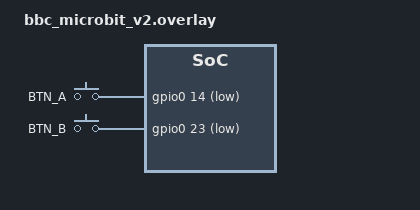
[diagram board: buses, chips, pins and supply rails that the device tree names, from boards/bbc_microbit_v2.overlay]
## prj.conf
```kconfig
#
# Copyright (c) 2018 Nordic Semiconductor
#
# SPDX-License-Identifier: LicenseRef-Nordic-5-Clause
#
CONFIG_NCS_SAMPLES_DEFAULTS=y

CONFIG_BT=y
CONFIG_BT_PERIPHERAL=y
CONFIG_BT_DEVICE_NAME="Nordic_LBS"

# Enable the LBS service
CONFIG_BT_LBS=y
CONFIG_BT_LBS_POLL_BUTTON=y
CONFIG_DK_LIBRARY=y

CONFIG_SYSTEM_WORKQUEUE_STACK_SIZE=2048

CONFIG_DISPLAY=y
CONFIG_MICROBIT_DISPLAY=y
CONFIG_BT_CTLR_TX_PWR_PLUS_8=y
```

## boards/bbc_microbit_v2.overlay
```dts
/*
 * Copyright (c) 2021 Nordic Semiconductor ASA
 *
 * SPDX-License-Identifier: LicenseRef-Nordic-5-Clause
 */

/ {
	buttons {
		compatible = "gpio-keys";
		button0: button_0 {
			label = "BTN_A";
			gpios = <&gpio0 14 GPIO_ACTIVE_LOW>;
			zephyr,code = <INPUT_KEY_A>;
		};

		button1: button_1 {
			label = "BTN_B";
			gpios = <&gpio0 23 GPIO_ACTIVE_LOW>;
			zephyr,code = <INPUT_KEY_B>;
		};
	};
};
```

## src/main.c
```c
/*
 * Copyright (c) 2018 Nordic Semiconductor ASA
 *
 * SPDX-License-Identifier: LicenseRef-Nordic-5-Clause
 */

#include <zephyr/types.h>
#include <stddef.h>
#include <string.h>
#include <errno.h>
#include <zephyr/sys/printk.h>
#include <zephyr/sys/byteorder.h>
#include <zephyr/kernel.h>
#include <zephyr/drivers/gpio.h>
#include <soc.h>

#include <zephyr/bluetooth/bluetooth.h>
#include <zephyr/bluetooth/hci.h>
#include <zephyr/bluetooth/conn.h>
#include <zephyr/bluetooth/uuid.h>
#include <zephyr/bluetooth/gatt.h>

#include <bluetooth/services/lbs.h>

#include <zephyr/settings/settings.h>

#include <dk_buttons_and_leds.h>

#include <zephyr/display/mb_display.h>

#define DEVICE_NAME             CONFIG_BT_DEVICE_NAME
#define DEVICE_NAME_LEN         (sizeof(DEVICE_NAME) - 1)


#define RUN_STATUS_LED          DK_LED1
#define CON_STATUS_LED          DK_LED2
#define RUN_LED_BLINK_INTERVAL  1000

#define USER_LED                DK_LED3

#define USER_BUTTON             DK_BTN1_MSK

static struct mb_image light_on = MB_IMAGE(
					 { 0, 1, 1, 1, 0 },
					 { 1, 0, 0, 0, 1 },
					 { 1, 0, 0, 0, 1 },
					 { 0, 1, 1, 1, 0 },
					 { 0, 1, 1, 1, 0 });

static struct mb_image light_off = MB_IMAGE(
					 { 0, 0, 0, 0, 0 },
					 { 0, 0, 0, 0, 0 },
					 { 0, 0, 0, 0, 0 },
					 { 0, 1, 1, 1, 0 },
					 { 0, 1, 1, 1, 0 });

static struct mb_image ble_disconnected = MB_IMAGE(
					 { 1, 0, 0, 0, 0 },
					 { 0, 0, 0, 0, 0 },
					 { 0, 0, 0, 0, 0 },
					 { 0, 0, 0, 0, 0 },
					 { 0, 0, 0, 0, 0 });

static struct mb_image blank = MB_IMAGE(
					 { 0, 0, 0, 0, 0 },
					 { 0, 0, 0, 0, 0 },
					 { 0, 0, 0, 0, 0 },
					 { 0, 0, 0, 0, 0 },
					 { 0, 0, 0, 0, 0 });

static bool app_button_state;
static bool app_led_state;
static bool ble_conn_state;
static struct mb_display *disp;

static const struct bt_data ad[] = {
	BT_DATA_BYTES(BT_DATA_FLAGS, (BT_LE_AD_GENERAL | BT_LE_AD_NO_BREDR)),
	BT_DATA(BT_DATA_NAME_COMPLETE, DEVICE_NAME, DEVICE_NAME_LEN),
};

static const struct bt_data sd[] = {
	BT_DATA_BYTES(BT_DATA_UUID128_ALL, BT_UUID_LBS_VAL),
};

static void connected(struct bt_conn *conn, uint8_t err)
{
	if (err) {
		printk("Connection failed (err %u)\n", err);
		return;
	}

	printk("Connected\n");

	if (app_led_state) {
		mb_display_image(disp, MB_DISPLAY_FLAG_LOOP, 5 * MSEC_PER_SEC,
				&light_on, 1);
	} else {
		mb_display_image(disp, MB_DISPLAY_FLAG_LOOP, 5 * MSEC_PER_SEC,
				&light_off, 1);
	}
	ble_conn_state = true;
}

static void disconnected(struct bt_conn *conn, uint8_t reason)
{
	printk("Disconnected (reason %u)\n", reason);

	//dk_set_led_off(CON_STATUS_LED);
	ble_conn_state = false;
}

#ifdef CONFIG_BT_LBS_SECURITY_ENABLED
static void security_changed(struct bt_conn *conn, bt_security_t level,
			     enum bt_security_err err)
{
	char addr[BT_ADDR_LE_STR_LEN];

	bt_addr_le_to_str(bt_conn_get_dst(conn), addr, sizeof(addr));

	if (!err) {
		printk("Security changed: %s level %u\n", addr, level);
	} else {
		printk("Security failed: %s level %u err %d\n", addr, level,
			err);
	}
}
#endif

BT_CONN_CB_DEFINE(conn_callbacks) = {
	.connected        = connected,
	.disconnected     = disconnected,
#ifdef CONFIG_BT_LBS_SECURITY_ENABLED
	.security_changed = security_changed,
#endif
};

#if defined(CONFIG_BT_LBS_SECURITY_ENABLED)
static void auth_passkey_display(struct bt_conn *conn, unsigned int passkey)
{
	char addr[BT_ADDR_LE_STR_LEN];

	bt_addr_le_to_str(bt_conn_get_dst(conn), addr, sizeof(addr));

	printk("Passkey for %s: %06u\n", addr, passkey);
}

static void auth_cancel(struct bt_conn *conn)
{
	char addr[BT_ADDR_LE_STR_LEN];

	bt_addr_le_to_str(bt_conn_get_dst(conn), addr, sizeof(addr));

	printk("Pairing cancelled: %s\n", addr);
}

static void pairing_complete(struct bt_conn *conn, bool bonded)
{
	char addr[BT_ADDR_LE_STR_LEN];

	bt_addr_le_to_str(bt_conn_get_dst(conn), addr, sizeof(addr));

	printk("Pairing completed: %s, bonded: %d\n", addr, bonded);
}

static void pairing_failed(struct bt_conn *conn, enum bt_security_err reason)
{
	char addr[BT_ADDR_LE_STR_LEN];

	bt_addr_le_to_str(bt_conn_get_dst(conn), addr, sizeof(addr));

	printk("Pairing failed conn: %s, reason %d\n", addr, reason);
}

static struct bt_conn_auth_cb conn_auth_callbacks = {
	.passkey_display = auth_passkey_display,
	.cancel = auth_cancel,
};

static struct bt_conn_auth_info_cb conn_auth_info_callbacks = {
	.pairing_complete = pairing_complete,
	.pairing_failed = pairing_failed
};
#else
static struct bt_conn_auth_cb conn_auth_callbacks;
static struct bt_conn_auth_info_cb conn_auth_info_callbacks;
#endif

static void app_led_cb(bool led_state)
{
	printk("led state: %d\n", led_state);
	app_led_state = led_state;
	if (app_led_state) {
		mb_display_image(disp, MB_DISPLAY_FLAG_LOOP, 5 * MSEC_PER_SEC,
				&light_on, 1);
	} else {
		mb_display_image(disp, MB_DISPLAY_FLAG_LOOP, 5 * MSEC_PER_SEC,
				&light_off, 1);
	}
}

static bool app_button_cb(void)
{
	return app_button_state;
}

static struct bt_lbs_cb lbs_callbacs = {
	.led_cb    = app_led_cb,
	.button_cb = app_button_cb,
};

static void button_changed(uint32_t button_state, uint32_t has_changed)
{
	if (has_changed & USER_BUTTON) {
		uint32_t user_button_state = button_state & USER_BUTTON;

		bt_lbs_send_button_state(user_button_state);
		app_button_state = user_button_state ? true : false;
		printk("app_button_state: %d\n", app_button_state);
	}
}

static int init_button(void)
{
	int err;

	err = dk_buttons_init(button_changed);
	if (err) {
		printk("Cannot init buttons (err: %d)\n", err);
	}

	return err;
}

int main(void)
{
	int blink_status = 0;
	int err;

	printk("Starting Bluetooth Peripheral LBS example\n");

	disp = mb_display_get();

	err = init_button();
	if (err) {
		printk("Button init failed (err %d)\n", err);
		return 0;
	}

	if (IS_ENABLED(CONFIG_BT_LBS_SECURITY_ENABLED)) {
		err = bt_conn_auth_cb_register(&conn_auth_callbacks);
		if (err) {
			printk("Failed to register authorization callbacks.\n");
			return 0;
		}

		err = bt_conn_auth_info_cb_register(&conn_auth_info_callbacks);
		if (err) {
			printk("Failed to register authorization info callbacks.\n");
			return 0;
		}
	}

	err = bt_enable(NULL);
	if (err) {
		printk("Bluetooth init failed (err %d)\n", err);
		return 0;
	}

	printk("Bluetooth initialized\n");

	if (IS_ENABLED(CONFIG_SETTINGS)) {
		settings_load();
	}

	err = bt_lbs_init(&lbs_callbacs);
	if (err) {
		printk("Failed to init LBS (err:%d)\n", err);
		return 0;
	}

	err = bt_le_adv_start(BT_LE_ADV_CONN, ad, ARRAY_SIZE(ad),
			      sd, ARRAY_SIZE(sd));
	if (err) {
		printk("Advertising failed to start (err %d)\n", err);
		return 0;
	}

	printk("Advertising successfully started\n");

	k_sleep(K_SECONDS(2));
	for (;;) {
		if (!ble_conn_state) {
			if ((++blink_status) % 2) {
				mb_display_image(disp, MB_DISPLAY_FLAG_LOOP, 1 * MSEC_PER_SEC,
						&ble_disconnected, 1);
			} else {
				mb_display_image(disp, MB_DISPLAY_FLAG_LOOP, 1 * MSEC_PER_SEC,
						&blank, 1);
			}
		}
		k_sleep(K_MSEC(RUN_LED_BLINK_INTERVAL));
	}
}
```
